# SDRC register map
Vendor: Texas Instruments
Peripheral module from a debugger description file (folder omap34xx).
Registers are 32-bit, read-write, reset 0x0 unless marked. A register's access mark holds for its fields unless they carry their own. Offsets are as the file gives them; lines under a group give offsets from that group; [hi:lo] are bit positions; {n}, {i} and the like mark numbered series; 'fields as' and 'values as' point back to an identical list; <NAME> marks a mode.

## SDRC
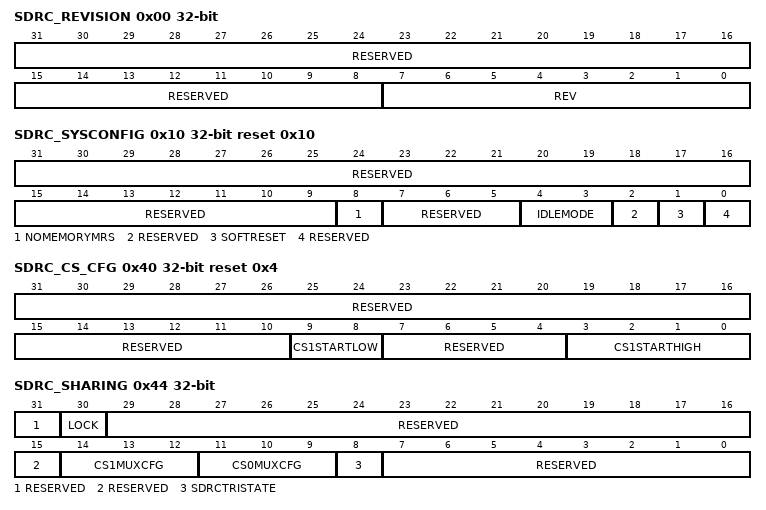
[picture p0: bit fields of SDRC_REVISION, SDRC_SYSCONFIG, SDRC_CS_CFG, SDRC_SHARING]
0x00 SDRC_REVISION ro (reset mask 0xFFFFFF00) — This register contains the IP revision code. This code is specified at design time.
  [31:8] RESERVED — Read returns 0.
  [7:0] REV — IP revision code[7:4]: Major revision[3:0]: Minor revisionExamples: 0x10 for 1.0, 0x21 for 2.1
0x10 SDRC_SYSCONFIG reset 0x10 — This register controls the various parameters of the interconnect.
  [31:9] RESERVED — Write 0s for future compatibilityRead returns 0.
  [8] NOMEMORYMRS — No external memory MRS command
    0=When set to 0, the SDRC internal and registers (both CS) are written and MR, EMR2 commands are performed to the corresponding registers of the external SDRAM; 1=When set to 1, only SDRC internal and registers (both CS) are written, no MR or EMR2 commands are performed to SDRAM
  [7:5] RESERVED — Write 0s for future compatibility.Read returns 0.
  [4:3] IDLEMODE — Power management Req/Ack control
    0=Reserved - Do not use; 1=Reserved - Do not use; 2=Smart Idle - Acknowledgment to an idle request is based on the internal activity of the module. Issued when the SDRC enters self-refresh.; 3=Reserved - Do not use
  [2] RESERVED — Write 0s for future compatibility. Read returns 0
  [1] SOFTRESET — Software reset
    0=Normal mode (no reset applied); 1=Software reset activated
  [0] RESERVED — Write 0s for future compatibility. Read returns 0.
0x14 SDRC_SYSSTATUS ro (reset mask 0xFFFFFFFE) — This register provides module status, excluding interrupt status info.
  [0] RESETDONE — Internal reset monitoring
    0=Internal module reset is ongoing; 1=Reset completed - The module is ready to be used
0x40 SDRC_CS_CFG reset 0x4 — This register configures the start address of CS1 address space. Must be aligned on a boundary that is a multiple of the size of the attached memory, or of the next power of two if the memory size is not a power of two.
  [31:10] RESERVED — Write 0s for future compatibility. Read returns 0.
  [9:8] CS1STARTLOW — CS1 address space start address (lower add bits a1:a0) / 32MB unit
  [7:4] RESERVED — Write 0s for future compatibility. Read returns 0.
  [3:0] CS1STARTHIGH — CS1 address space start address (upper add bits a5:a4:a3:a2) / 128MB unit
0x44 SDRC_SHARING (reset mask 0x80000000) — This register specifies the SDRC attached memory size and position on the SDRC IOs.
  [31] RESERVED — Write 0s for future compatibility.Read returns 0.
  [30] LOCK — Read-only access lock bit
    0=This register is fully writable; 1=When this bit is set, the register can not be unset until next reset of the module
  [29:15] RESERVED — Write 0s for future compatibility.Read returns 0s.
  [14:12] CS1MUXCFG — Identifies the SDRC pins used by CS1
    0=32-bit SDRAM on Datalane[31:0]; 1=32-bit SDRAM on Datalane[31:0]; 2=16-bit SDRAM on Datalane[31:16]; 3=16-bit SDRAM on Datalane[16:0]; 7=16-bit SDRAM on Datalane[31:16]
  [11:9] CS0MUXCFG — Identifies the SDRC pins used by CS0
    values as CS1MUXCFG
  [8] SDRCTRISTATE — Static 3-state command for the SDRC I/O pads
    0=All SDRC interface pins are set to hi-Z; 1=Normal mode: SDRC drives the I/O pads based on the memory traffic
  [7:0] RESERVED — Write 0s for future compatibility. Read returns 0s.
0x48 SDRC_ERR_ADDR ro — This register captures the address of the last illegal access received on the interconnect.
  [31:0] ERRORADDRESS — Address of illegal access (Bit 31 is always 0.)
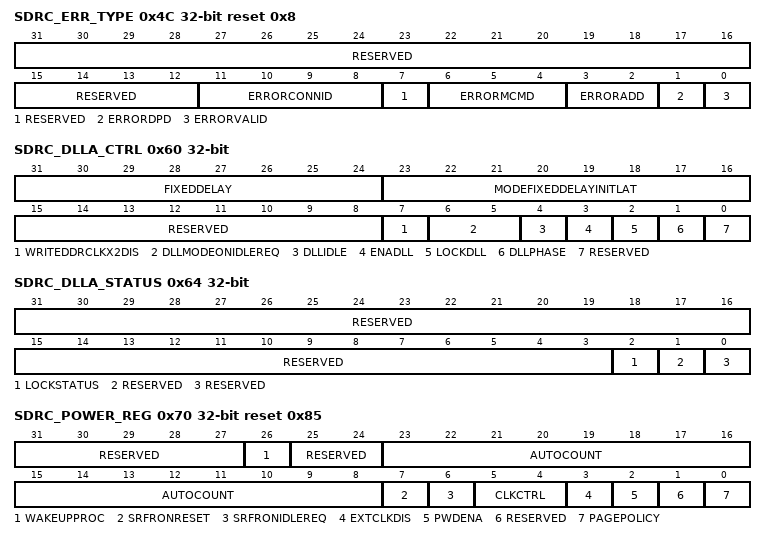
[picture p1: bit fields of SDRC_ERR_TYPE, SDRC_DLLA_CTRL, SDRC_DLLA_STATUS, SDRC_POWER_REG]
0x4C SDRC_ERR_TYPE reset 0x8 — This register provides additional information about the last illegal access.
  [31:12] RESERVED — Write 0s for future compatibility. Read returns 0.
  [11:8] ERRORCONNID — Identifies the interconnect ConnID of the illegal access initiator: Refer to the top level documentation of the device using the SDRC module.
  [7] RESERVED — Write 0 for future compatibility. Read returns 0.
  [6:4] ERRORMCMD — System command of the transaction that caused the error (3-bit field)
  [3:2] ERRORADD — Flag that indicates access is to an illegal address
    0=ERRORADD_0_r (The system request was to an address outside the memory space.); 0=ERRORADD_0_w (Clear ErrorAdd bit field.); 1=ERRORADD_1_r (The system request was to an address outside the register space.); 1=ERRORADD_1_w (No effect); 2=ERRORADD_2_r (No Err Add. Not an address error); 2=ERRORADD_2_w (No effect); 3=ERRORADD_3_r (No Err Add. Not an address error); 3=ERRORADD_3_w (No effect)
  [1] ERRORDPD — Transaction error while the memory is in deep-power-down mode
    0=ERRORDPD_0_r (The memory was not in deep-power-down mode when the error occurred.); 0=ERRORDPD_0_w (No effect); 1=ERRORDPD_1_r (The error is due to an unexpected access while the memory was in deep-power-down mode.); 1=ERRORDPD_1_w (Clear the ErrorDPD bit field.)
  [0] ERRORVALID — Error validity status - Must be explicitly cleared with a write 0 transaction.
    0=ERRORVALID_0_r (All error fields no longer valid); 0=ERRORVALID_0_w (Clear ErrorValid bit field); 1=ERRORVALID_1_r (Error detected and logged in the other error fields); 1=ERRORVALID_1_w (No effect)
0x60 SDRC_DLLA_CTRL — This register controls the SDRC DLL A resource used for fine timing tuning on a double-data-rate interface.
  [31:24] FIXEDDELAY — Phase offset value in ModeFixedDelay mode. Maximum frequency supported in this mode is 83 MHz. FIXEDDELAY steps are defined after DLL cell characterization.
  [23:16] MODEFIXEDDELAYINITLAT — Initial latency before first request to be processed in ModeFixedDelay mode 0x0: no initial latency before first access 0x1: 2 clock cycles before first access0x2: 4 clock cycles before first access 0x3: 6 clock cycles before first access 0x4 : 8 clock cycles before first access ...0xFF: 510 clock cycles before first access
  [15:8] RESERVED — Write 0s for future compatibility. Read returns 0.
  [7] WRITEDDRCLKX2DIS — Disable MDDR write path using the double frequency input clock.
    0=MDDR write path using the double frequency clock logic; 1=MDDR write path using the DLL/CDL write path logic
  [6:5] DLLMODEONIDLEREQ — Selects the DLL mode upon hardware idle request
    0=DLL in Power-down mode upon hardware idle request; 1=DLL in DLL idle mode upon hardware idle request; 2=No action upon hardware idle request. Input clock frequency must not be changed.; 3=Reserved for future use (no action upon hardware idle request)
  [4] DLLIDLE — Enables the DLL Idle mode
    0=DLL Idle mode disabled; 1=DLL Idle mode enabled
  [3] ENADLL — Enables DLL
    0=DLL disabled; 1=DLL enabled
  [2] LOCKDLL — Selects the DLL functionality between the TrackingDelay mode (previously called lock mode) or the ModeFixedDelay mode (previously called unlock mode). The DLL mode is updated in the DLL cell after:- DLLIDLE mode- DLL power-down mode
    0=LOCKDLL at 0 puts the DLL in TrackingDelay mode (tracking counter started); 1=LOCKDLL at 1 puts the DLL in ModeFixedDelay mode. The fixed delay defined in FIXEDDELAY bit field is used to delay DQS lines for read accesses.
  [1] DLLPHASE — Nominal digitally-controlled delay when DLL is enabled
    0=72 degrees (20% of the clock period); 1=90 degrees (25% of the clock cycle)
  [0] RESERVED — Write 0s for future compatibility. Reads return 0.
0x64 SDRC_DLLA_STATUS ro — This register reflects the current status of the DLL A.
  [31:3] RESERVED — Reads return zeros.
  [2] LOCKSTATUS — DLL lock status
    0=The DLL is not locked; 1=The DLL is locked
  [1] RESERVED — Reads return zero.
  [0] RESERVED — Reads return zero.
0x70 SDRC_POWER_REG reset 0x85 — This SDRC power-management register defines the global power-management policy (shared by CS0/CS1).
  [31:27] RESERVED — Write 0s for future compatibility.Read returns 0.
  [26] WAKEUPPROC — Select if after a SDRC wakeup in DDR mode (in DLL tracking-delay mode), the first request is stalled during 500 cycles latency or until the lock signal from the DLL/CDL analog cell is asserted.
    0=SDRC allows DDR access after 500 L3 clock cycles; 1=SDRC allows DDR access as soon as DLL LOCKSTATUS bit is 1
  [25:24] RESERVED — Write 0s for future compatibility.Read returns 0.
  [23:8] AUTOCOUNT — 16-bit programmable count value used for delayed automatic clock gating and self-refresh entry, assuming CLKCTRL field is not 0
  [7] SRFRONRESET — Enter self refresh when a warm reset is applied:
    0=Feature disabled; 1=Feature enabled
  [6] SRFRONIDLEREQ — Enter self refresh when on hardware idle request:
    0=Feature disabled; 1=Feature enabled
  [5:4] CLKCTRL — Clock control feature defines clock gating and self refresh:
    0=No auto clk feature turned on; 1=Enable internal clock gating on timeout of Auto_cnt; 2=Enable self-refresh on timeout of Auto_cnt
  [3] EXTCLKDIS — Disable the clock provided to the external memories:
    0=Enable clock; 1=Disable clock- Logical 0 is applied
  [2] PWDENA — Activate the power-down mode of the target memory through CKE pin.
    0=Power-down mode feature disabled; 1=Power-down mode feature enabled
  [1] RESERVED — Write 0 for future compatibility. Read returns 0.
  [0] PAGEPOLICY — Page/segment closure policy with respect to power versus bandwidth trade-off - Must be set to 1
    0=Reserved - must not be used; 1=High-power/high bandwidth mode (HPHB)
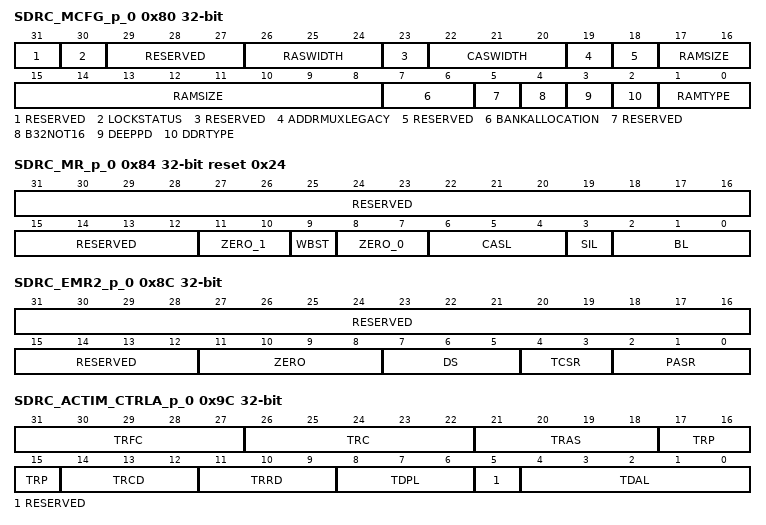
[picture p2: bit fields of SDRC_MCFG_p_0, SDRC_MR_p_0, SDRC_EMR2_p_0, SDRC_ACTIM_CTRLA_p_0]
0x80 SDRC_MCFG_p_0 (reset mask 0x80000000) — This register provides the memory configuration register.
  [31] RESERVED — Write 0s for future compatibility. Read returns 0.
  [30] LOCKSTATUS — Read-only access lock bit
    values as SDRC_SHARING.LOCK
  [29:27] RESERVED — Write 0s for future compatibility. Read returns 0.
  [26:24] RASWIDTH — RAS address width
    {v}=RAS width = {v+11} bits (v=0..4); 5=RAS width = 16 bits - Must not be used; 6=RAS width = 17 bits - Must not be used; 7=RAS width = 18 bits - Must not be used
  [23] RESERVED — Write 0s for future compatibility. Read returns 0.
  [22:20] CASWIDTH — CAS address width
    {v}=CAS width = {v+5} bits (v=0..7)
  [19] ADDRMUXLEGACY — Selects the fixed address-muxing scheme or the flexible address-muxing scheme
    0=Fixed address mux scheme; 1=Flexible address mux scheme
  [18] RESERVED — Write 0s for future compatibility. Read returns 0.
  [17:8] RAMSIZE — RAM address space size number of 2-MB chunks
  [7:6] BANKALLOCATION — SDRAM banks mapping. Selects the position of the bank address, the row address, and the column address in the system address.
    0=Bank-row-column; 1=Bank1-row-bank0-column; 2=Row-bank-column
  [5] RESERVED — Write 0s for future compatibility. Read returns 0.
  [4] B32NOT16 — External SDRAM bus width
    0=External SDRAM device is x16 bit; 1=External SDRAM device is x32 bit
  [3] DEEPPD — Indicates if the memory supports deep-power-down mode
    0=No deep-power-down mode support; 1=The memory supports deep-power-down mode
  [2] DDRTYPE — DDR memory type (assuming RAMTYPE = 01)
    0=Mobile DDR; 1=Reserved for future use
  [1:0] RAMTYPE — Memory type
    0=SDR-SDRAM (single data rate); 1=DDR-SDRAM (double data rate)
0x84 SDRC_MR_p_0 reset 0x24 — This 12-bit register corresponds to the JEDEC SDRAM MR register, with the standard bit fields. All 12 bits are loaded into memory for future extension support. The SDRC keeps an internal copy register used internally; that is, returned when a read access is performed at that address. Load into memory on interconnect write access using MRS command with BA1,BA0 = 0,0.
  [31:12] RESERVED — Write 0s for future compatibility. Read returns 0s.
  [11:10] ZERO_1 — Write 0s, as required by memory specifications. Read returns 0.
  [9] WBST — Write burst support must be zero.
    0=Write burst equals read burst; 1=Write burst disable (single write access only)
  [8:7] ZERO_0 — Write 0s, as required by memory specifications. Read returns 0s.
  [6:4] CASL — CAS latency as defined by clock periods
    {v}=CAS latency = {v} (v=1..5)
  [3] SIL — Serial or interleaved mode: must be zero
    0=Serial mode (always used); 1=interleaved mode (never used)
  [2:0] BL — Memory burst length
    0=Burst length = 1 - Not supported; 1=Burst length = 2 - SDR memory only; 2=Burst length = 4 - DDR memory only; 3=Burst length = 8 - Not supported; 7=Full page - Not supported
0x8C SDRC_EMR2_p_0 — This 12-bit register corresponds to the low-power EMR register, as defined in the mobile DDR JEDEC Standard. All 12 bits are loaded into the memory, thus assuring future extension support. The SDRC keeps an internal copy register used internally; that is, returned when a read access is performed at that address. Load into memory on interconnect write access using MRS command with BA1,BA0 = 1,0.
  [31:12] RESERVED — Write 0s for future compatibility. Read returns 0s.
  [11:8] ZERO — Write 0s, as required by memory specifications. Read returns 0
  [7:5] DS — Driver strength
    0=Full strength driver; 1=Half strength driver; 4=Three-fourths strength driver; 6=Optional one-fourth strength driver; 7=Optional one-eighth strength driver
  [4:3] TCSR — Temperature-compensated self-refresh
    0=70 degrees maximum temperature; 1=45 degrees maximum temperature; 2=15 degrees maximum temperature; 3=85 degrees maximum temperature
  [2:0] PASR — Partial array self-refresh
    0=All banks; 1=1/2 array; 2=1/4 array; 5=1/8 array; 6=1/16 array
0x9C SDRC_ACTIM_CTRLA_p_0 — The ac timing control register A sets the ac parameter values in clock cycle units to best match the memory characteristics.
  [31:27] TRFC — Autorefresh to active
  [26:22] TRC — Row cycle time
  [21:18] TRAS — Row active time
  [17:15] TRP — Row precharge time
  [14:12] TRCD — Row to column delay time
  [11:9] TRRD — Active to active command period
  [8:6] TDPL — Data-in to precharge command (write recovery time tWR)
  [5] RESERVED — Write 0s for future compatibility. Read returns 0.
  [4:0] TDAL — Data-in to active command
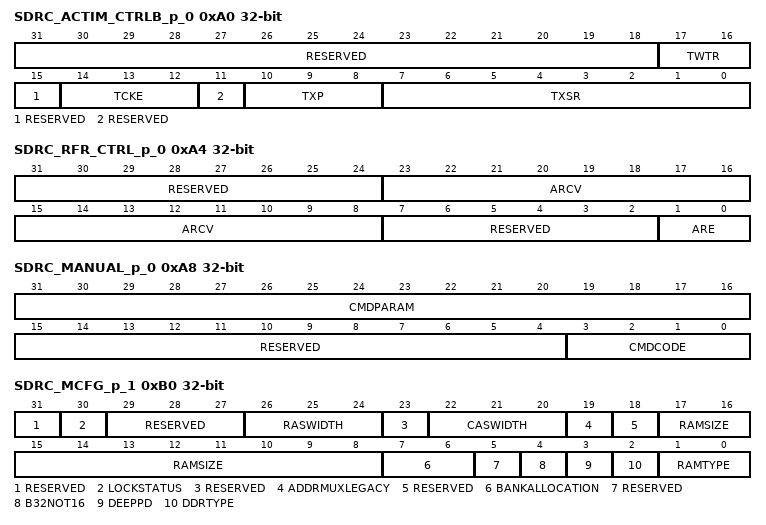
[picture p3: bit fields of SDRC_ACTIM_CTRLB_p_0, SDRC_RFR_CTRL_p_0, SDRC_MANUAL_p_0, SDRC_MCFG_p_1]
0xA0 SDRC_ACTIM_CTRLB_p_0 — The ac timing control register B sets the ac parameter values in clock cycle unit, to best match the memory characteristics
  [31:18] RESERVED — Write 0s for future compatibilityReads return zeros.
  [17:16] TWTR — Internal write to read command delay.0x0: 1 minimum clock cycle before next command0x1: 1 minimum clock cycle0x2: 2 minimum clock cycles0x3: 3 minimum clock cycles
  [15] RESERVED — Write 0s for future compatibilityReads return zeros.
  [14:12] TCKE — CKE minimum pulse width (high and low)0x0: 1 minimum clock cycle0x1: 1 minimum clock cycle0x2: 2 minimum clock cycles...0x7: 7 minimum clock cycles
  [11] RESERVED — Write 0s for future compatibilityReads return zeros.
  [10:8] TXP — Exit power-down to next valid command delay.0x0: 1 minimum clock cycle before next command0x1: 1 minimum clock cycle0x2: 2 minimum clock cycles...0x7: 7 minimum clock cycles
  [7:0] TXSR — Self-refresh exit to active period
0xA4 SDRC_RFR_CTRL_p_0 — SDRAM memory autorefresh control
  [31:24] RESERVED — Write 0s for future compatibility. Read returns 0.
  [23:8] ARCV — Autorefresh counter value to set the refresh period. The autorefresh counter is uploaded with the result of:(tREFI / tCK) - 50
  [7:2] RESERVED — Write 0s for future compatibility. Read returns 0.
  [1:0] ARE — Autorefresh enable
    0=Autorefresh is disabled; 1=Counter is loaded with ARCV: 1 autorefresh command when autorefresh counter reaches 0; 2=Counter is loaded with 4 ×ARCV: Burst of 4 autorefresh commands when autorefresh counter reaches 0; 3=Counter is loaded with 8 ×ARCV: Burst of 8 autorefresh commands when autorefresh counter reaches 0
0xA8 SDRC_MANUAL_p_0 — This register allows to send specific commands to the external memory devices under software control. Any write to this register generates the appropriate sequence based on the command code.
  [31:16] CMDPARAM — Manual command parameter, if any.
  [15:4] RESERVED — Write 0s for future compatibility. Read returns 0s.
  [3:0] CMDCODE — Memory command opcode; other values reserved for future implementations.
    0=NOP command - no parameter; 1=Precharge all command - no parameter; 2=Autorefresh command - no parameter; 3=Enter deep-power-down - no parameter; 4=Exit deep-power-down - no parameter; 5=Enter self-refresh - no parameter; 6=Exit self-refresh - no parameter; 7=Set CKE signal high - no parameter; 8=Set CKE low - no parameter
0xB0 SDRC_MCFG_p_1 (reset mask 0x80000000) — This register provides the memory configuration register.
  fields as SDRC_MCFG_p_0
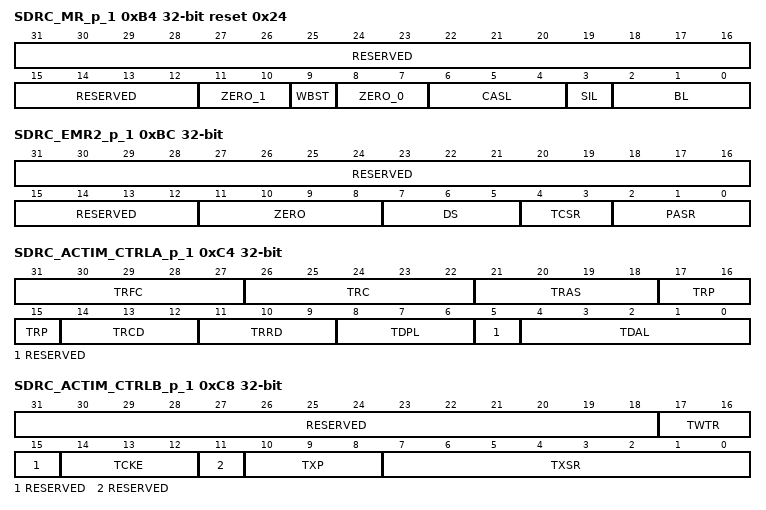
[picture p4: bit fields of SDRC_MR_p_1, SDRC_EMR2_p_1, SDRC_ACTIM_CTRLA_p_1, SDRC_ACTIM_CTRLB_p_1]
0xB4 SDRC_MR_p_1 reset 0x24 — This 12-bit register corresponds to the JEDEC SDRAM MR register, with the standard bit fields. All 12 bits are loaded into memory for future extension support. The SDRC keeps an internal copy register used internally; that is, returned when a read access is performed at that address. Load into memory on interconnect write access using MRS command with BA1,BA0 = 0,0.
  fields as SDRC_MR_p_0
0xBC SDRC_EMR2_p_1 — This 12-bit register corresponds to the low-power EMR register, as defined in the mobile DDR JEDEC Standard. All 12 bits are loaded into the memory, thus assuring future extension support. The SDRC keeps an internal copy register used internally; that is, returned when a read access is performed at that address. Load into memory on interconnect write access using MRS command with BA1,BA0 = 1,0.
  fields as SDRC_EMR2_p_0
0xC4 SDRC_ACTIM_CTRLA_p_1 — The ac timing control register A sets the ac parameter values in clock cycle units to best match the memory characteristics.
  fields as SDRC_ACTIM_CTRLA_p_0
0xC8 SDRC_ACTIM_CTRLB_p_1 — The ac timing control register B sets the ac parameter values in clock cycle unit, to best match the memory characteristics
  fields as SDRC_ACTIM_CTRLB_p_0
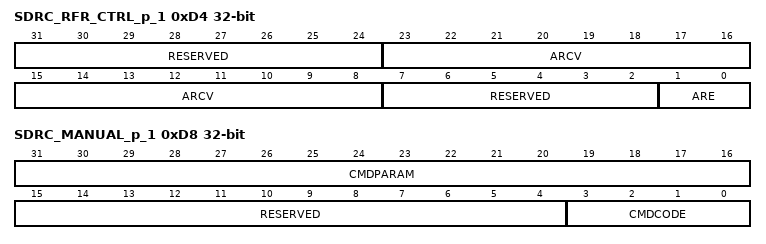
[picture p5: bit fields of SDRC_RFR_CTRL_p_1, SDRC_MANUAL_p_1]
0xD4 SDRC_RFR_CTRL_p_1 — SDRAM memory autorefresh control
  fields as SDRC_RFR_CTRL_p_0
0xD8 SDRC_MANUAL_p_1 — This register allows to send specific commands to the external memory devices under software control. Any write to this register generates the appropriate sequence based on the command code.
  fields as SDRC_MANUAL_p_0
